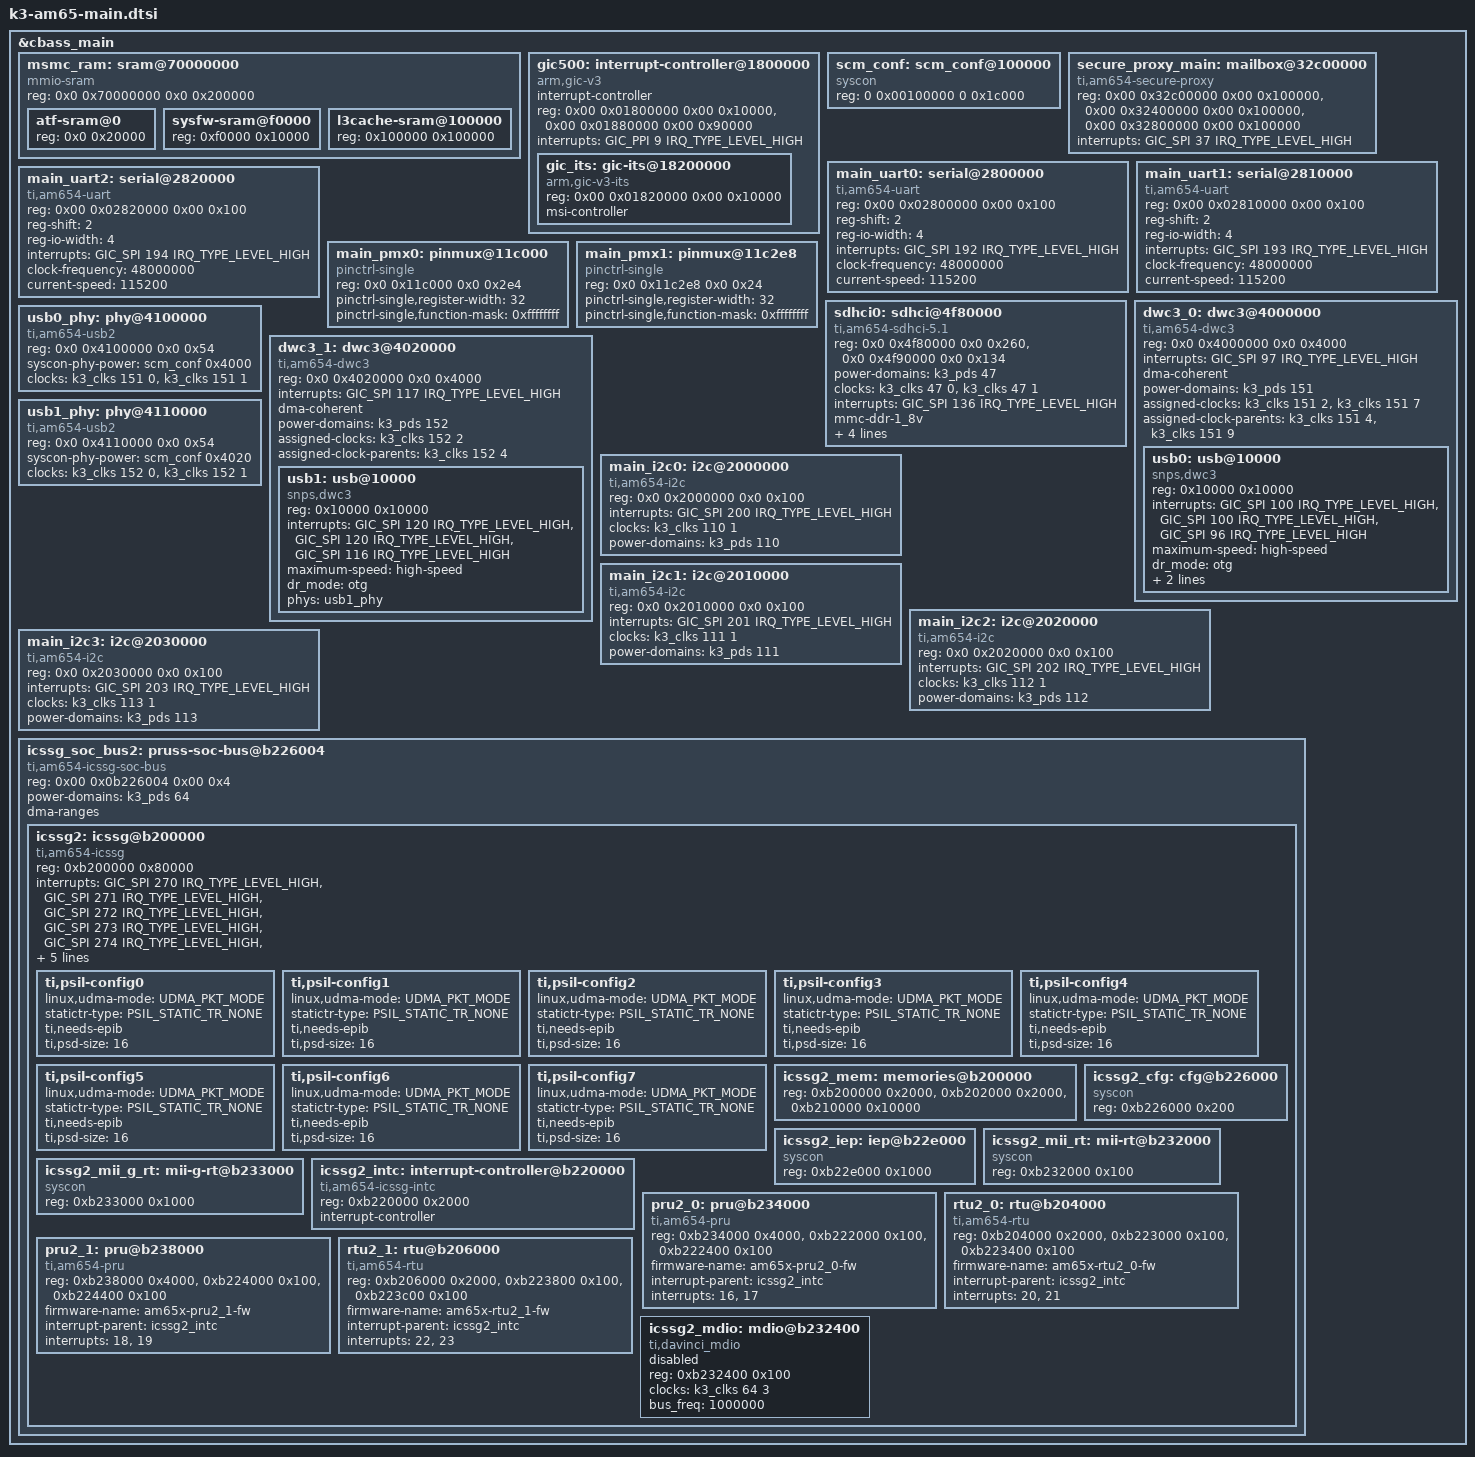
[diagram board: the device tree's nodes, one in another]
// SPDX-License-Identifier: GPL-2.0
/*
 * Device Tree Source for AM6 SoC Family Main Domain peripherals
 *
 * Copyright (C) 2016-2018 Texas Instruments Incorporated - http://www.ti.com/
 */

#include <dt-bindings/dma/k3-udma.h>

&cbass_main {
	msmc_ram: sram@70000000 {
		compatible = "mmio-sram";
		reg = <0x0 0x70000000 0x0 0x200000>;
		#address-cells = <1>;
		#size-cells = <1>;
		ranges = <0x0 0x0 0x70000000 0x200000>;
		u-boot,dm-spl;

		atf-sram@0 {
			reg = <0x0 0x20000>;
		};

		sysfw-sram@f0000 {
			reg = <0xf0000 0x10000>;
		};

		l3cache-sram@100000 {
			reg = <0x100000 0x100000>;
		};
	};

	gic500: interrupt-controller@1800000 {
		compatible = "arm,gic-v3";
		#address-cells = <2>;
		#size-cells = <2>;
		ranges;
		#interrupt-cells = <3>;
		interrupt-controller;
		reg = <0x00 0x01800000 0x00 0x10000>,	/* GICD */
		      <0x00 0x01880000 0x00 0x90000>;	/* GICR */
		/*
		 * vcpumntirq:
		 * virtual CPU interface maintenance interrupt
		 */
		interrupts = <GIC_PPI 9 IRQ_TYPE_LEVEL_HIGH>;

		gic_its: gic-its@18200000 {
			compatible = "arm,gic-v3-its";
			reg = <0x00 0x01820000 0x00 0x10000>;
			msi-controller;
			#msi-cells = <1>;
		};
	};

	scm_conf: scm_conf@100000 {
		compatible = "syscon", "simple-mfd";
		reg = <0 0x00100000 0 0x1c000>;
		#address-cells = <1>;
		#size-cells = <1>;
		ranges = <0x0 0x0 0x00100000 0x1c000>;
	};

	secure_proxy_main: mailbox@32c00000 {
		compatible = "ti,am654-secure-proxy";
		#mbox-cells = <1>;
		reg-names = "target_data", "rt", "scfg";
		reg = <0x00 0x32c00000 0x00 0x100000>,
		      <0x00 0x32400000 0x00 0x100000>,
		      <0x00 0x32800000 0x00 0x100000>;
		interrupt-names = "rx_011";
		interrupts = <GIC_SPI 37 IRQ_TYPE_LEVEL_HIGH>;
	};

	main_uart0: serial@2800000 {
		compatible = "ti,am654-uart";
		reg = <0x00 0x02800000 0x00 0x100>;
		reg-shift = <2>;
		reg-io-width = <4>;
		interrupts = <GIC_SPI 192 IRQ_TYPE_LEVEL_HIGH>;
		clock-frequency = <48000000>;
		current-speed = <115200>;
	};

	main_uart1: serial@2810000 {
		compatible = "ti,am654-uart";
		reg = <0x00 0x02810000 0x00 0x100>;
		reg-shift = <2>;
		reg-io-width = <4>;
		interrupts = <GIC_SPI 193 IRQ_TYPE_LEVEL_HIGH>;
		clock-frequency = <48000000>;
		current-speed = <115200>;
	};

	main_uart2: serial@2820000 {
		compatible = "ti,am654-uart";
		reg = <0x00 0x02820000 0x00 0x100>;
		reg-shift = <2>;
		reg-io-width = <4>;
		interrupts = <GIC_SPI 194 IRQ_TYPE_LEVEL_HIGH>;
		clock-frequency = <48000000>;
		current-speed = <115200>;
	};

	main_pmx0: pinmux@11c000 {
		compatible = "pinctrl-single";
		reg = <0x0 0x11c000 0x0 0x2e4>;
		#pinctrl-cells = <1>;
		pinctrl-single,register-width = <32>;
		pinctrl-single,function-mask = <0xffffffff>;
	};

	main_pmx1: pinmux@11c2e8 {
		compatible = "pinctrl-single";
		reg = <0x0 0x11c2e8 0x0 0x24>;
		#pinctrl-cells = <1>;
		pinctrl-single,register-width = <32>;
		pinctrl-single,function-mask = <0xffffffff>;
	};

	sdhci0: sdhci@4f80000 {
		compatible = "ti,am654-sdhci-5.1";
		reg = <0x0 0x4f80000 0x0 0x260>, <0x0 0x4f90000 0x0 0x134>;
		power-domains = <&k3_pds 47>;
		clocks = <&k3_clks 47 0>, <&k3_clks 47 1>;
		clock-names = "clk_ahb", "clk_xin";
		interrupts = <GIC_SPI 136 IRQ_TYPE_LEVEL_HIGH>;
		mmc-ddr-1_8v;
		mmc-hs200-1_8v;
		ti,otap-del-sel = <0x2>;
		ti,trm-icp = <0x8>;
		dma-coherent;
	};

	scm_conf: scm_conf@100000 {
		compatible = "syscon", "simple-mfd";
		reg = <0 0x00100000 0 0x1c000>;
		#address-cells = <1>;
		#size-cells = <1>;
		ranges = <0x0 0x0 0x00100000 0x1c000>;
	};

	dwc3_0: dwc3@4000000 {
		compatible = "ti,am654-dwc3";
		reg = <0x0 0x4000000 0x0 0x4000>;
		#address-cells = <1>;
		#size-cells = <1>;
		ranges = <0x0 0x0 0x4000000 0x20000>;
		interrupts = <GIC_SPI 97 IRQ_TYPE_LEVEL_HIGH>;
		dma-coherent;
		power-domains = <&k3_pds 151>;
		assigned-clocks = <&k3_clks 151 2>, <&k3_clks 151 7>;
		assigned-clock-parents = <&k3_clks 151 4>,	/* set REF_CLK to 20MHz i.e. PER0_PLL/48 */
					 <&k3_clks 151 9>;	/* set PIPE3_TXB_CLK to CLK_12M_RC/256 (for HS only) */

		usb0: usb@10000 {
			compatible = "snps,dwc3";
			reg = <0x10000 0x10000>;
			interrupts = <GIC_SPI 100 IRQ_TYPE_LEVEL_HIGH>,
				     <GIC_SPI 100 IRQ_TYPE_LEVEL_HIGH>,
				     <GIC_SPI 96 IRQ_TYPE_LEVEL_HIGH>;
			interrupt-names = "peripheral",
					  "host",
					  "otg";
			maximum-speed = "high-speed";
			dr_mode = "otg";
			phys = <&usb0_phy>;
			phy-names = "usb2-phy";
			snps,dis_u3_susphy_quirk;
		};
	};

	usb0_phy: phy@4100000 {
		compatible = "ti,am654-usb2", "ti,omap-usb2";
		reg = <0x0 0x4100000 0x0 0x54>;
		syscon-phy-power = <&scm_conf 0x4000>;
		clocks = <&k3_clks 151 0>, <&k3_clks 151 1>;
		clock-names = "wkupclk", "refclk";
		#phy-cells = <0>;
	};

	dwc3_1: dwc3@4020000 {
		compatible = "ti,am654-dwc3";
		reg = <0x0 0x4020000 0x0 0x4000>;
		#address-cells = <1>;
		#size-cells = <1>;
		ranges = <0x0 0x0 0x4020000 0x20000>;
		interrupts = <GIC_SPI 117 IRQ_TYPE_LEVEL_HIGH>;
		dma-coherent;
		power-domains = <&k3_pds 152>;
		assigned-clocks = <&k3_clks 152 2>;
		assigned-clock-parents = <&k3_clks 152 4>;	/* set REF_CLK to 20MHz i.e. PER0_PLL/48 */

		usb1: usb@10000 {
			compatible = "snps,dwc3";
			reg = <0x10000 0x10000>;
			interrupts = <GIC_SPI 120 IRQ_TYPE_LEVEL_HIGH>,
				     <GIC_SPI 120 IRQ_TYPE_LEVEL_HIGH>,
				     <GIC_SPI 116 IRQ_TYPE_LEVEL_HIGH>;
			interrupt-names = "peripheral",
					  "host",
					  "otg";
			maximum-speed = "high-speed";
			dr_mode = "otg";
			phys = <&usb1_phy>;
			phy-names = "usb2-phy";
		};
	};

	usb1_phy: phy@4110000 {
		compatible = "ti,am654-usb2", "ti,omap-usb2";
		reg = <0x0 0x4110000 0x0 0x54>;
		syscon-phy-power = <&scm_conf 0x4020>;
		clocks = <&k3_clks 152 0>, <&k3_clks 152 1>;
		clock-names = "wkupclk", "refclk";
		#phy-cells = <0>;
	};

	main_i2c0: i2c@2000000 {
		compatible = "ti,am654-i2c", "ti,omap4-i2c";
		reg = <0x0 0x2000000 0x0 0x100>;
		interrupts = <GIC_SPI 200 IRQ_TYPE_LEVEL_HIGH>;
		#address-cells = <1>;
		#size-cells = <0>;
		clock-names = "fck";
		clocks = <&k3_clks 110 1>;
		power-domains = <&k3_pds 110>;
	};

	main_i2c1: i2c@2010000 {
		compatible = "ti,am654-i2c", "ti,omap4-i2c";
		reg = <0x0 0x2010000 0x0 0x100>;
		interrupts = <GIC_SPI 201 IRQ_TYPE_LEVEL_HIGH>;
		#address-cells = <1>;
		#size-cells = <0>;
		clock-names = "fck";
		clocks = <&k3_clks 111 1>;
		power-domains = <&k3_pds 111>;
	};

	main_i2c2: i2c@2020000 {
		compatible = "ti,am654-i2c", "ti,omap4-i2c";
		reg = <0x0 0x2020000 0x0 0x100>;
		interrupts = <GIC_SPI 202 IRQ_TYPE_LEVEL_HIGH>;
		#address-cells = <1>;
		#size-cells = <0>;
		clock-names = "fck";
		clocks = <&k3_clks 112 1>;
		power-domains = <&k3_pds 112>;
	};

	main_i2c3: i2c@2030000 {
		compatible = "ti,am654-i2c", "ti,omap4-i2c";
		reg = <0x0 0x2030000 0x0 0x100>;
		interrupts = <GIC_SPI 203 IRQ_TYPE_LEVEL_HIGH>;
		#address-cells = <1>;
		#size-cells = <0>;
		clock-names = "fck";
		clocks = <&k3_clks 113 1>;
		power-domains = <&k3_pds 113>;
	};

	icssg_soc_bus2: pruss-soc-bus@b226004 {
		compatible = "ti,am654-icssg-soc-bus", "simple-bus";
		reg = <0x00 0x0b226004 0x00 0x4>;
		power-domains = <&k3_pds 64>;
		#address-cells = <1>;
		#size-cells = <1>;
		ranges = <0x0b200000 0x00 0x0b200000 0x100000>;
		dma-ranges;

		icssg2: icssg@b200000 {
			compatible = "ti,am654-icssg";
			reg = <0xb200000 0x80000>;
			interrupts = <GIC_SPI 270 IRQ_TYPE_LEVEL_HIGH>,
				     <GIC_SPI 271 IRQ_TYPE_LEVEL_HIGH>,
				     <GIC_SPI 272 IRQ_TYPE_LEVEL_HIGH>,
				     <GIC_SPI 273 IRQ_TYPE_LEVEL_HIGH>,
				     <GIC_SPI 274 IRQ_TYPE_LEVEL_HIGH>,
				     <GIC_SPI 275 IRQ_TYPE_LEVEL_HIGH>,
				     <GIC_SPI 276 IRQ_TYPE_LEVEL_HIGH>,
				     <GIC_SPI 277 IRQ_TYPE_LEVEL_HIGH>;
			interrupt-names = "host2", "host3", "host4",
					  "host5", "host6", "host7",
					  "host8", "host9";
			#address-cells = <1>;
			#size-cells = <1>;
			ranges;
			dma-ranges;
			ti,psil-base = <0x4300>;	/* ICSSG2 PSIL thread start */

			ti,psil-config0 {
				linux,udma-mode = <UDMA_PKT_MODE>;
				statictr-type = <PSIL_STATIC_TR_NONE>;
				ti,needs-epib;
				ti,psd-size = <16>;
			};

			ti,psil-config1 {
				linux,udma-mode = <UDMA_PKT_MODE>;
				statictr-type = <PSIL_STATIC_TR_NONE>;
				ti,needs-epib;
				ti,psd-size = <16>;
			};

			ti,psil-config2 {
				linux,udma-mode = <UDMA_PKT_MODE>;
				statictr-type = <PSIL_STATIC_TR_NONE>;
				ti,needs-epib;
				ti,psd-size = <16>;
			};

			ti,psil-config3 {
				linux,udma-mode = <UDMA_PKT_MODE>;
				statictr-type = <PSIL_STATIC_TR_NONE>;
				ti,needs-epib;
				ti,psd-size = <16>;
			};

			ti,psil-config4 {
				linux,udma-mode = <UDMA_PKT_MODE>;
				statictr-type = <PSIL_STATIC_TR_NONE>;
				ti,needs-epib;
				ti,psd-size = <16>;
			};

			ti,psil-config5 {
				linux,udma-mode = <UDMA_PKT_MODE>;
				statictr-type = <PSIL_STATIC_TR_NONE>;
				ti,needs-epib;
				ti,psd-size = <16>;
			};

			ti,psil-config6 {
				linux,udma-mode = <UDMA_PKT_MODE>;
				statictr-type = <PSIL_STATIC_TR_NONE>;
				ti,needs-epib;
				ti,psd-size = <16>;
			};

			ti,psil-config7 {
				linux,udma-mode = <UDMA_PKT_MODE>;
				statictr-type = <PSIL_STATIC_TR_NONE>;
				ti,needs-epib;
				ti,psd-size = <16>;
			};

			icssg2_mem: memories@b200000 {
				reg = <0xb200000 0x2000>,
				      <0xb202000 0x2000>,
				      <0xb210000 0x10000>;
				reg-names = "dram0", "dram1",
					    "shrdram2";
			};

			icssg2_cfg: cfg@b226000 {
				compatible = "syscon";
				reg = <0xb226000 0x200>;
			};

			icssg2_iep: iep@b22e000 {
				compatible = "syscon";
				reg = <0xb22e000 0x1000>;
			};

			icssg2_mii_rt: mii-rt@b232000 {
				compatible = "syscon";
				reg = <0xb232000 0x100>;
			};

			icssg2_mii_g_rt: mii-g-rt@b233000 {
				compatible = "syscon";
				reg = <0xb233000 0x1000>;
			};

			icssg2_intc: interrupt-controller@b220000 {
				compatible = "ti,am654-icssg-intc";
				reg = <0xb220000 0x2000>;
				interrupt-controller;
				#interrupt-cells = <1>;
			};

			pru2_0: pru@b234000 {
				compatible = "ti,am654-pru";
				reg = <0xb234000 0x4000>,
				      <0xb222000 0x100>,
				      <0xb222400 0x100>;
				reg-names = "iram", "control", "debug";
				firmware-name = "am65x-pru2_0-fw";
				interrupt-parent = <&icssg2_intc>;
				interrupts = <16>, <17>;
				interrupt-names = "vring", "kick";
			};

			rtu2_0: rtu@b204000 {
				compatible = "ti,am654-rtu";
				reg = <0xb204000 0x2000>,
				      <0xb223000 0x100>,
				      <0xb223400 0x100>;
				reg-names = "iram", "control", "debug";
				firmware-name = "am65x-rtu2_0-fw";
				interrupt-parent = <&icssg2_intc>;
				interrupts = <20>, <21>;
				interrupt-names = "vring", "kick";
			};

			pru2_1: pru@b238000 {
				compatible = "ti,am654-pru";
				reg = <0xb238000 0x4000>,
				      <0xb224000 0x100>,
				      <0xb224400 0x100>;
				reg-names = "iram", "control", "debug";
				firmware-name = "am65x-pru2_1-fw";
				interrupt-parent = <&icssg2_intc>;
				interrupts = <18>, <19>;
				interrupt-names = "vring", "kick";
			};

			rtu2_1: rtu@b206000 {
				compatible = "ti,am654-rtu";
				reg = <0xb206000 0x2000>,
				      <0xb223800 0x100>,
				      <0xb223c00 0x100>;
				reg-names = "iram", "control", "debug";
				firmware-name = "am65x-rtu2_1-fw";
				interrupt-parent = <&icssg2_intc>;
				interrupts = <22>, <23>;
				interrupt-names = "vring", "kick";
			};

			icssg2_mdio: mdio@b232400 {
				compatible = "ti,davinci_mdio";
				reg = <0xb232400 0x100>;
				clocks = <&k3_clks 64 3>;
				clock-names = "fck";
				#address-cells = <1>;
				#size-cells = <0>;
				bus_freq = <1000000>;
				status = "disabled";
			};
		};
	};
};
